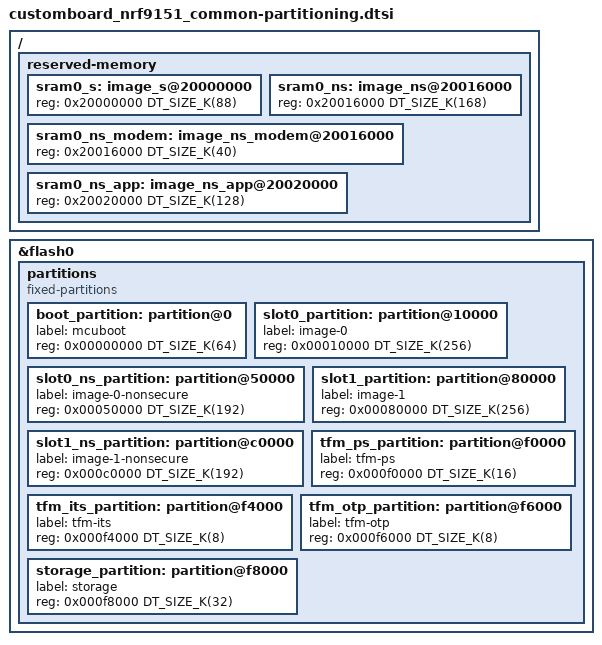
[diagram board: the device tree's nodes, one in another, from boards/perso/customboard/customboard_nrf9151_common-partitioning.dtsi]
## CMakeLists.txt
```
cmake_minimum_required(VERSION 3.20.0)

message(STATUS "Found ZEPHYR_BASE env: $ENV{ZEPHYR_BASE}")
set(CMAKE_MODULE_PATH
  "$ENV{ZEPHYR_BASE}/share/zephyr-package/cmake"
  )

# Configure board and required zephyr modules.
# Assumption here is that if not explicitly specified the zephyr modules are
# installed alongside the ZEPHYR_BASE directory.
if(NOT BOARD)
  set(BOARD "customboard/stm32h562xx")
  message(STATUS "Use default board: ${BOARD}")
endif()
if(NOT ZEPHYR_MODULES_BASE)
  set(ZEPHYR_MODULES_BASE "$ENV{ZEPHYR_BASE}/../modules")
endif()
list(APPEND ZEPHYR_MODULES
  ${ZEPHYR_MODULES_BASE}/hal/cmsis
  ${ZEPHYR_MODULES_BASE}/hal/stm32
  ${CMAKE_CURRENT_SOURCE_DIR}/modules
  )
list(APPEND BOARD_ROOT ${CMAKE_CURRENT_SOURCE_DIR})
find_package(Zephyr REQUIRED HINTS $ENV{ZEPHYR_BASE})

project(zephyr_test)

list(APPEND app_sources
  src/main.c
  src/utils/threads.c
  src/utils/threads.h
  )
target_sources(app PRIVATE ${app_sources})

# vim: set sw=2 sts=2 et :
```

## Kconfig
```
mainmenu "Zephy test application configuration"

config TEST_CUSTOM_STRING
        string "Custom test string"
        default "test.custom.org"
        help
	  This feature not actively used, it demonstrates the use of a custom
	  string defined in Kconfig.

config TEST_CUSTOM_INT
        int "Custom test integer"
        default 128
        depends on TEST_CUSTOM_BOOL
        help
	  Dummy integer used as demonstration for application configuration within
	  a Kconfig file.

config TEST_CUSTOM_BOOL
        bool "Enable TEST_CUSTOM_INT"

source "Kconfig.zephyr"
```

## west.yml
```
manifest:
  remotes:
    - name: zephyrproject-rtos
      url-base: https://github.com/zephyrproject-rtos

  projects:
    - name: zephyr
      remote: zephyrproject-rtos
      revision: v4.0-branch
      import:
        # By using name-allowlist we can clone only the modules that are
        # strictly needed by the application.
        name-allowlist:
          - cmsis    # required by the ARM port for Cortex-M
          - hal_stm32  # required by the nucleo_f302r8 board (STM32 based)

# vim: set sw=2 sts=2 :
```

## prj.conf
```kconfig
CONFIG_DEBUG=y
CONFIG_DEBUG_OPTIMIZATIONS=y

CONFIG_GPIO=y

# System configuration
#CONFIG_MAIN_STACK_SIZE=8192
#CONFIG_SYSTEM_WORKQUEUE_STACK_SIZE=4096

# Configure printf support
CONFIG_CBPRINTF_COMPLETE=y
CONFIG_CBPRINTF_FP_SUPPORT=y
CONFIG_PRINTK_SYNC=y

# Enable the JSON lib
CONFIG_JSON_LIBRARY=y

# Enable Flash control and persistent storage
CONFIG_FLASH=y
CONFIG_FLASH_MAP=y
CONFIG_ZMS=y
CONFIG_FLASH_LOG_LEVEL_INF=y
CONFIG_ZMS_LOG_LEVEL_DBG=y

# Logging
CONFIG_LOG=y
#CONFIG_LOG_BUFFER_SIZE=65536
CONFIG_LOG_MODE_IMMEDIATE=n
# Print logs and printk() output on uart0.
CONFIG_LOG_BACKEND_UART=y

# Config stack analyzer
CONFIG_THREAD_STACK_INFO=y
CONFIG_THREAD_NAME=y
CONFIG_THREAD_MONITOR=y
#CONFIG_THREAD_ANALYZER=y
#CONFIG_THREAD_ANALYZER_USE_PRINTK=y
#CONFIG_THREAD_ANALYZER_AUTO=y
#CONFIG_THREAD_ANALYZER_AUTO_INTERVAL=5
```

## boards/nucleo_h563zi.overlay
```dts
/ {
  chosen {
    zephyr,console = &usart3;
  };
};
```

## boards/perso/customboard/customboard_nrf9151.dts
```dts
/dts-v1/;
#include <nordic/nrf9151_laca.dtsi>
#include "customboard_nrf9151_common.dtsi"

/ {
  chosen {
    zephyr,flash = &flash0;
    zephyr,sram = &sram0_s;
    zephyr,code-partition = &slot0_partition;
    zephyr,sram-secure-partition = &sram0_s;
    zephyr,sram-non-secure-partition = &sram0_ns;
  };
};
```

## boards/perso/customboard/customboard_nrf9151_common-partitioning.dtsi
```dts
/*
 * Default Flash planning for nRF91 series SoCs.
 * This layout matches (by necessity) that in the TF-M repository:
 *
 * 0x0000_0000 BL2 - MCUBoot (64 KB)
 * 0x0001_0000 Primary image area (448 KB):
 *    0x0001_0000 Secure     image primary (256 KB)
 *    0x0005_0000 Non-secure image primary (192 KB)
 * 0x0008_0000 Secondary image area (448 KB):
 *    0x0008_0000 Secure     image secondary (256 KB)
 *    0x000c_0000 Non-secure image secondary (192 KB)
 * 0x000f_0000 Protected Storage Area (16 KB)
 * 0x000f_4000 Internal Trusted Storage Area (8 KB)
 * 0x000f_6000 OTP / NV counters area (8 KB)
 * 0x000f_8000 Non-secure storage, used when built with NRF_NS_STORAGE=ON,

 *             otherwise unused (32 KB)
 */

&flash0 {
	partitions {
		compatible = "fixed-partitions";
		#address-cells = <1>;
		#size-cells = <1>;

		boot_partition: partition@0 {
			label = "mcuboot";
			reg = <0x00000000 DT_SIZE_K(64)>;
		};

		slot0_partition: partition@10000 {
			label = "image-0";
			reg = <0x00010000 DT_SIZE_K(256)>;
		};

		slot0_ns_partition: partition@50000 {
			label = "image-0-nonsecure";
			reg = <0x00050000 DT_SIZE_K(192)>;
		};

		slot1_partition: partition@80000 {
			label = "image-1";
			reg = <0x00080000 DT_SIZE_K(256)>;
		};

		slot1_ns_partition: partition@c0000 {
			label = "image-1-nonsecure";
			reg = <0x000c0000 DT_SIZE_K(192)>;
		};

		tfm_ps_partition: partition@f0000 {
			label = "tfm-ps";
			reg = <0x000f0000 DT_SIZE_K(16)>;
		};

		tfm_its_partition: partition@f4000 {
			label = "tfm-its";
			reg = <0x000f4000 DT_SIZE_K(8)>;
		};

		tfm_otp_partition: partition@f6000 {
			label = "tfm-otp";
			reg = <0x000f6000 DT_SIZE_K(8)>;
		};

		storage_partition: partition@f8000 {
			label = "storage";
			reg = <0x000f8000 DT_SIZE_K(32)>;
		};
	};
};


/*
 * Default SRAM planning when building for nRF91xx with
 * ARM TrustZone-M support
 * - Lowest 88 kB SRAM allocated to Secure image (sram0_s).
 * - Upper 168 kB SRAM allocated to Non-Secure image (sram0_ns).
 * Of the memory allocated to the Non-Secure image
 * - 40 kB SRAM reserved for and used by the modem library (sram0_ns_modem).
 * - 128 kB allocated to the application (sram0_ns_app).
 */
/ {
	reserved-memory {
		#address-cells = <1>;
		#size-cells = <1>;
		ranges;

		sram0_s: image_s@20000000 {
			/* Secure image memory */
			reg = <0x20000000 DT_SIZE_K(88)>;
		};

		sram0_ns: image_ns@20016000 {
				/* Non-Secure image memory */
				reg = <0x20016000 DT_SIZE_K(168)>;
		};

		sram0_ns_modem: image_ns_modem@20016000 {
				/* Modem (shared) memory */
				reg = <0x20016000 DT_SIZE_K(40)>;
		};

		sram0_ns_app: image_ns_app@20020000 {
				/* Non-Secure application memory */
				reg = <0x20020000 DT_SIZE_K(128)>;
		};
	};
};
```

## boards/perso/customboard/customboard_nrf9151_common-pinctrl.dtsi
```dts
&pinctrl {
  uart0_default: uart0_default {
    group1 {
      psels = <NRF_PSEL(UART_TX, 0, 28)>,
        <NRF_PSEL(UART_RTS, 0, 26)>;
    };
    group2 {
      psels = <NRF_PSEL(UART_RX, 0, 29)>,
        <NRF_PSEL(UART_CTS, 0, 27)>;
      bias-pull-up;
    };
  };

  uart0_sleep: uart0_sleep {
    group1 {
      psels = <NRF_PSEL(UART_TX, 0, 28)>,
        <NRF_PSEL(UART_RX, 0, 29)>,
        <NRF_PSEL(UART_RTS, 0, 26)>,
        <NRF_PSEL(UART_CTS, 0, 27)>;
      low-power-enable;
    };
  };

  uart2_default: uart2_default {
    group1 {
      psels = <NRF_PSEL(UART_TX, 0, 12)>,
        <NRF_PSEL(UART_RTS, 0, 15)>;
    };
    group2 {
      psels = <NRF_PSEL(UART_RX, 0, 13)>,
        <NRF_PSEL(UART_CTS, 0, 14)>;
      bias-pull-up;
    };
  };

  uart2_sleep: uart2_sleep {
    group1 {
      psels = <NRF_PSEL(UART_TX, 0, 12)>,
        <NRF_PSEL(UART_RX, 0, 13)>,
        <NRF_PSEL(UART_RTS, 0, 15)>,
        <NRF_PSEL(UART_CTS, 0, 14)>;
      low-power-enable;
    };
  };
};
```

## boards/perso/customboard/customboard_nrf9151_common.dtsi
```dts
#include "customboard_nrf9151_common-partitioning.dtsi"
#include "customboard_nrf9151_common-pinctrl.dtsi"
#include <zephyr/dt-bindings/input/input-event-codes.h>

/ {
  model = "Perso CustomBoard (NRF91)";
  compatible = "perso,customboard-nrf91";

  chosen {
    zephyr,console = &uart0;
    zephyr,shell-uart = &uart0;
    zephyr,uart-mcumgr = &uart0;
    ncs,slm-uart = &uart2;
  };

  aliases {
    watchdog0 = &wdt0;
    mcuboot-button0 = &button0;
  };

  buttons {
    compatible = "gpio-keys";
    button0: button_0 {
      gpios = <&gpio0 23 (GPIO_PULL_UP | GPIO_ACTIVE_LOW)>;
      label = "Push button 1";
      zephyr,code = <INPUT_KEY_0>;
    };
  };
};

&gpiote {
  status = "okay";
};

&gpio0 {
  status = "okay";
};

&uart0 {
  status = "okay";
  current-speed = <115200>;
  pinctrl-0 = <&uart0_default>;
  pinctrl-1 = <&uart0_sleep>;
  pinctrl-names = "default", "sleep";
  // Disable flow control except when necessary, otherwise no application using UART0
  // for log output will be able to work properly without a USB/UART adaptor connected.
  //hw-flow-control;
};

&uart2 {
  status = "okay";
  current-speed = <115200>;
  pinctrl-0 = <&uart2_default>;
  pinctrl-1 = <&uart2_sleep>;
  pinctrl-names = "default", "sleep";
  hw-flow-control;
};
```

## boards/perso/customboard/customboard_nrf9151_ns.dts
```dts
/dts-v1/;
#include <nordic/nrf9151ns_laca.dtsi>
#include "customboard_nrf9151_common.dtsi"

/ {
  chosen {
    zephyr,flash = &flash0;
    zephyr,sram = &sram0_ns_app;
    zephyr,code-partition = &slot0_ns_partition;
  };
};

/* Disable UART1, because it is used by default in TF-M */
&uart1 {
  status = "disabled";
};
```

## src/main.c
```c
#include <zephyr/kernel.h>
#include <zephyr/device.h>
#include <zephyr/drivers/gpio.h>

#include "utils/threads.h"

// Configure push button and LED
#define SW0_NODE DT_ALIAS(sw0)
#if !DT_NODE_HAS_STATUS_OKAY(SW0_NODE)
  #error "sw0 devicetree alias is not defined"
#endif
static const struct gpio_dt_spec button = GPIO_DT_SPEC_GET(SW0_NODE, gpios);
static struct gpio_callback button_cb_data; // holder for button callback

static const struct gpio_dt_spec led = GPIO_DT_SPEC_GET(DT_ALIAS(led0), gpios);
static int64_t blink_time = 0;


static void button_pressed(const struct device *dev,
                           struct gpio_callback *cb,
                           uint32_t pins)
{
  printk("Button pressed at %" PRIu32 "\n", k_cycle_get_32());
}

int main(void)
{
  int res;

  printk("Configure button and LED\n");
  if (0 != (res = gpio_pin_configure_dt(&button, GPIO_INPUT))) {
    printk("Error %d: failed to configure %s pin %d\n",
           res, button.port->name, button.pin);
    return 0;
  }
  res = gpio_pin_interrupt_configure_dt(&button, GPIO_INT_EDGE_TO_ACTIVE);
  if (res) {
    printk("Error %d: failed to configure interrupt on %s pin %d\n",
           res, button.port->name, button.pin);
    return 0;
  }
  gpio_init_callback(&button_cb_data, button_pressed, BIT(button.pin));
  gpio_add_callback(button.port, &button_cb_data);
  printk("Set up button at %s pin %d\n", button.port->name, button.pin);

  // Test LEDs
  if (!gpio_is_ready_dt(&led)) {
    printk("Led not ready\n");
    return 0;
  }

  res = gpio_pin_configure_dt(&led, GPIO_OUTPUT_ACTIVE);
  if (res < 0) {
    printk("Error while configuring led: %d\n", res);
    return 0;
  }

  // Print all threads
  threads_print();

  while (1) {
    // Give some time to other threads
    k_msleep(1);
  }

  return 0;
}

// vim: set sw=2 sts=2 et :
```
